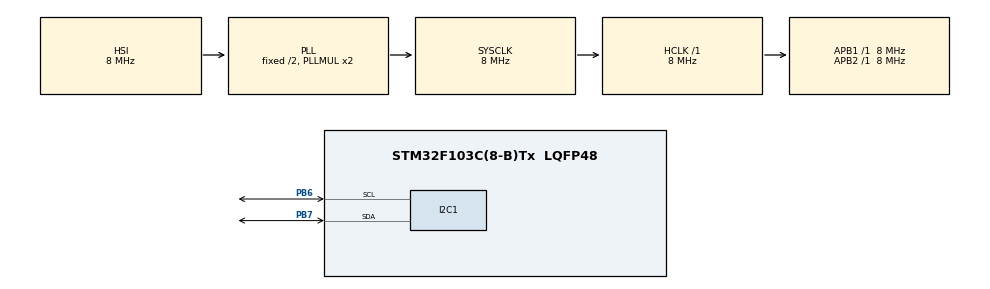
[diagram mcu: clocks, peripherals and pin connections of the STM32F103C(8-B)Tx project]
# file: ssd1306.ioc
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I2C1.I2C_Mode=I2C_Fast
Mcu.Family=STM32F1
Mcu.Name=STM32F103C(8-B)Tx
Mcu.Package=LQFP48
NVIC.PriorityGroup=NVIC_PRIORITYGROUP_4
PA13.Mode=Serial_Wire
PA13.Signal=SYS_JTMS-SWDIO
PA14.Mode=Serial_Wire
PA14.Signal=SYS_JTCK-SWCLK
PB6.Mode=I2C
PB6.Signal=I2C1_SCL
PB7.Mode=I2C
PB7.Signal=I2C1_SDA
ProjectManager.HeapSize=0x200
ProjectManager.StackSize=0x400
ProjectManager.TargetToolchain=STM32CubeIDE
RCC.AHBFreq_Value=8000000
RCC.APB1Freq_Value=8000000
RCC.APB1TimFreq_Value=8000000
RCC.APB2Freq_Value=8000000
RCC.APB2TimFreq_Value=8000000
RCC.HCLKFreq_Value=8000000
RCC.SYSCLKFreq_VALUE=8000000
RCC.SYSCLKSource=RCC_SYSCLKSOURCE_PLLCLK
RCC.USBFreq_Value=8000000
VP_CRC_VS_CRC.Mode=CRC_Activate
board=custom

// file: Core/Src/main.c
/* USER CODE BEGIN Header */
/**
  ******************************************************************************
  * @file           : main.c
  * @brief          : Main program body
  ******************************************************************************
  * @attention
  *
  * Copyright (c) 2026 STMicroelectronics.
  * All rights reserved.
  *
  * This software is licensed under terms that can be found in the LICENSE file
  * in the root directory of this software component.
  * If no LICENSE file comes with this software, it is provided AS-IS.
  *
  ******************************************************************************
  */
/* USER CODE END Header */
#include "main.h"
#include <string.h>
#include <math.h>

/* USER CODE BEGIN PD */
#define DeactivateScroll 0x2E
#define ActivateScroll 0x2F
#define NOP 0xE3
#define SetSegmentReMap 0xA0
#define EntireDisplayON 0xA4
#define SetNormalInverseDisplay 0xA6
#define SetDisplayONOFF 0xAE
#define SetCOMOutputScanDirection 0xC0
#define ChargePumpSetting 0x8D
#define SetVCOMHDeselectLevel 0xDB
#define SetMemoryAddressingMode 0x20
#define SetCOMPinsHardwareConfiguration 0xDA
#define SetPageStartAddressForPageAddressingMode 0xB0
#define SetHigherColumnStartAddressForPageAddressingMode 0x10
#define SetLowerColumnStartAddressForPageAddressingMode
#define SetPageAddress 0x22
#define SetDisplayStartLine 0x40
#define SetMultiplexRatio 0xA8
#define SetDisplayOffset 0xD3
#define SetColumnAddress 0x21
#define SetContrastControl 0x81
#define SetDisplayClockDivideRatioOscillatorFrequency 0xD5
#define SetPrechargePeriod 0xD9
#define ContinuousHorizontalScrollSetup 0x26
#define SetVerticalScrollArea 0xA3
#define ContinuousVerticalAndHorizontalScrollSetup 0x29
#define DisplayOn 0xAF
#define COMSCANDEC 0xC8

#define SlaveAddress 0x3C

const uint8_t char1[]={0x1C, 0x00, 0x22, 0xC0, 0x22, 0x40, 0x22, 0x40, 0x1F, 0x80, 0x00, 0x00};
/* USER CODE END PD */

CRC_HandleTypeDef hcrc;

I2C_HandleTypeDef hi2c1;

void SystemClock_Config(void);
static void MX_GPIO_Init(void);
static void MX_CRC_Init(void);
static void MX_I2C1_Init(void);

void send_cmd(uint8_t slave_address,uint8_t D, uint8_t cmd, uint8_t *payload, uint16_t length){
	  uint8_t data[1+length+1];
	  data[0]=D;
	  data[1]=cmd;
	  memcpy(&data[2], payload, length);
	  HAL_I2C_Master_Transmit(&hi2c1, slave_address<<1, data, sizeof(data), 10);
}
void send_data(uint8_t slave_address,uint8_t D, uint8_t payload, uint16_t length){
	  uint8_t data[1+length];
	  data[0]=D;
	  memcpy(&data[1], &payload, length);
	  HAL_I2C_Master_Transmit(&hi2c1, slave_address<<1, data, sizeof(data), 10);
}
void ssd1306_init(){
	uint8_t init[][2]={
			{SetDisplayONOFF, 0x00},
			{SetDisplayClockDivideRatioOscillatorFrequency, 0x80},
			{SetMultiplexRatio, 0x3F},
			{SetDisplayOffset, 0x00},
			{SetDisplayStartLine, 0x00},
			{ChargePumpSetting, 0x14},
			{SetMemoryAddressingMode, 0x00},
			{SetSegmentReMap, 0x00},
			{COMSCANDEC, 0x00},
			{SetCOMPinsHardwareConfiguration, 0x12},
			{SetContrastControl, 0xCF},
			{SetPrechargePeriod, 0xF1},
			{SetVCOMHDeselectLevel, 0x40},
			{EntireDisplayON, 0x00},
			{SetNormalInverseDisplay, 0x00},
			{DisplayOn, 0x00}
	};
	for(uint8_t i=0; i<(sizeof(init)/sizeof(init[0])); i++){
		send_cmd(SlaveAddress,0x00, init[i][0], &init[i][1], 1);
	}
}
void ssd1306_fill(uint8_t fill){

    for(uint8_t page=0; page<8; page++){
    		for(uint8_t seg=0; seg<=127; seg++){
    			send_data(SlaveAddress, 0x40, fill, 1);
    		}
    	}
}
void ssd1306_clear(){
	for(uint8_t page=0; page<8; page++){
		for(uint8_t seg=0; seg<= 127; seg++){
			send_data(SlaveAddress, 0x40, 0x00, 1);
		}
	}

}
void ssd1306_set_cursor(uint8_t row, uint8_t col){
	uint8_t page=row/8;
	//uint8_t bit=row%8;
	send_cmd(SlaveAddress, 0x00, SetPageStartAddressForPageAddressingMode+page, 0x00,1);
	send_cmd(SlaveAddress, 0x00, 0x00|(col & 0x0F), 0x00, 1);
	send_cmd(SlaveAddress, 0x00, 0x10|(col>>4), 0x00, 1);

}
int main(void)
{

  /* MCU Configuration--------------------------------------------------------*/

  /* Reset of all peripherals, Initializes the Flash interface and the Systick. */
  HAL_Init();

  /* Configure the system clock */
  SystemClock_Config();

  /* Initialize all configured peripherals */
  MX_GPIO_Init();
  MX_CRC_Init();
  MX_I2C1_Init();
  /* USER CODE BEGIN 2 */
  ssd1306_init();
//  for(uint8_t i=0x01; i<=0xFF; i++){
//  			  ssd1306_fill(i);
//  			  HAL_Delay(200);
//  		  }
  /* USER CODE END 2 */

  /* Infinite loop */
  /* USER CODE BEGIN WHILE */
  ssd1306_clear();
  ssd1306_fill(0x01);
  		  HAL_Delay(100);
  		  ssd1306_fill(0x0F);
  		  HAL_Delay(100);
  		  ssd1306_fill(0xFF);
  		 HAL_Delay(400);
  while (1)
  {
    /* USER CODE END WHILE */

	  for(uint8_t n=0; n<12; n++){
			send_data(SlaveAddress, 0x40, char1[n], 1);
	  }
	  for(uint8_t i=0; i<8; i++){
		  for(uint8_t i=0; i<128; i++){
			  send_data(SlaveAddress, 0x40, 0x00, 1);
		  }
	  }

  }
}

void SystemClock_Config(void)
{
  RCC_OscInitTypeDef RCC_OscInitStruct = {0};
  RCC_ClkInitTypeDef RCC_ClkInitStruct = {0};

  /** Initializes the RCC Oscillators according to the specified parameters
  * in the RCC_OscInitTypeDef structure.
  */
  RCC_OscInitStruct.OscillatorType = RCC_OSCILLATORTYPE_HSI;
  RCC_OscInitStruct.HSIState = RCC_HSI_ON;
  RCC_OscInitStruct.HSICalibrationValue = RCC_HSICALIBRATION_DEFAULT;
  RCC_OscInitStruct.PLL.PLLState = RCC_PLL_ON;
  RCC_OscInitStruct.PLL.PLLSource = RCC_PLLSOURCE_HSI_DIV2;
  RCC_OscInitStruct.PLL.PLLMUL = RCC_PLL_MUL2;
  if (HAL_RCC_OscConfig(&RCC_OscInitStruct) != HAL_OK)
  {
    Error_Handler();
  }

  /** Initializes the CPU, AHB and APB buses clocks
  */
  RCC_ClkInitStruct.ClockType = RCC_CLOCKTYPE_HCLK|RCC_CLOCKTYPE_SYSCLK
                              |RCC_CLOCKTYPE_PCLK1|RCC_CLOCKTYPE_PCLK2;
  RCC_ClkInitStruct.SYSCLKSource = RCC_SYSCLKSOURCE_PLLCLK;
  RCC_ClkInitStruct.AHBCLKDivider = RCC_SYSCLK_DIV1;
  RCC_ClkInitStruct.APB1CLKDivider = RCC_HCLK_DIV1;
  RCC_ClkInitStruct.APB2CLKDivider = RCC_HCLK_DIV1;

  if (HAL_RCC_ClockConfig(&RCC_ClkInitStruct, FLASH_LATENCY_0) != HAL_OK)
  {
    Error_Handler();
  }
}

static void MX_CRC_Init(void)
{

  hcrc.Instance = CRC;
  if (HAL_CRC_Init(&hcrc) != HAL_OK)
  {
    Error_Handler();
  }

}

static void MX_I2C1_Init(void)
{

  hi2c1.Instance = I2C1;
  hi2c1.Init.ClockSpeed = 400000;
  hi2c1.Init.DutyCycle = I2C_DUTYCYCLE_2;
  hi2c1.Init.OwnAddress1 = 0;
  hi2c1.Init.AddressingMode = I2C_ADDRESSINGMODE_7BIT;
  hi2c1.Init.DualAddressMode = I2C_DUALADDRESS_DISABLE;
  hi2c1.Init.OwnAddress2 = 0;
  hi2c1.Init.GeneralCallMode = I2C_GENERALCALL_DISABLE;
  hi2c1.Init.NoStretchMode = I2C_NOSTRETCH_DISABLE;
  if (HAL_I2C_Init(&hi2c1) != HAL_OK)
  {
    Error_Handler();
  }

}

static void MX_GPIO_Init(void)
{

  /* GPIO Ports Clock Enable */
  __HAL_RCC_GPIOA_CLK_ENABLE();
  __HAL_RCC_GPIOB_CLK_ENABLE();

}

void Error_Handler(void)
{
  __disable_irq();
  while (1)
  {
  }
}
